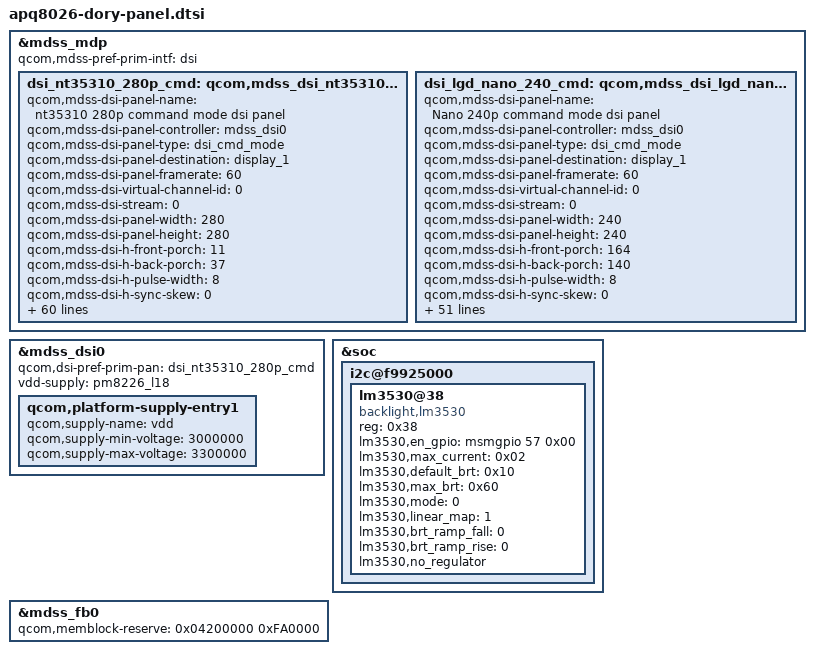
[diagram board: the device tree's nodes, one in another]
/* Copyright (c) 2013, Code Aurora Forum. All rights reserved.
 * Copyright (c) 2013, LGE Inc.
 *
 * This program is free software; you can redistribute it and/or modify
 * it under the terms of the GNU General Public License version 2 and
 * only version 2 as published by the Free Software Foundation.
 *
 * This program is distributed in the hope that it will be useful,
 * but WITHOUT ANY WARRANTY; without even the implied warranty of
 * MERCHANTABILITY or FITNESS FOR A PARTICULAR PURPOSE.  See the
 * GNU General Public License for more details.
 */

&mdss_mdp {
	qcom,mdss-pref-prim-intf = "dsi";
	dsi_nt35310_280p_cmd: qcom,mdss_dsi_nt35310_280p_cmd {
		qcom,mdss-dsi-panel-name = "nt35310 280p command mode dsi panel";
		qcom,mdss-dsi-panel-controller = <&mdss_dsi0>;
		qcom,mdss-dsi-panel-type = "dsi_cmd_mode";
		qcom,mdss-dsi-panel-destination = "display_1";
		qcom,mdss-dsi-panel-framerate = <60>;
		qcom,mdss-dsi-virtual-channel-id = <0>;
		qcom,mdss-dsi-stream = <0>;
		qcom,mdss-dsi-panel-width = <280>;
		qcom,mdss-dsi-panel-height = <280>;
		qcom,mdss-dsi-h-front-porch = <11>;
		qcom,mdss-dsi-h-back-porch = <37>;
		qcom,mdss-dsi-h-pulse-width = <8>;
		qcom,mdss-dsi-h-sync-skew = <0>;
		qcom,mdss-dsi-v-back-porch = <16>;
		qcom,mdss-dsi-v-front-porch = <30>;
		qcom,mdss-dsi-v-pulse-width = <1>;
		qcom,mdss-dsi-h-left-border = <0>;
		qcom,mdss-dsi-h-right-border = <0>;
		qcom,mdss-dsi-v-top-border = <0>;
		qcom,mdss-dsi-v-bottom-border = <0>;
		qcom,mdss-pan-physical-width-dimension = < 30 >;
		qcom,mdss-pan-physical-height-dimension = < 30 >;
		qcom,mdss-dsi-bpp = <24>;
		qcom,mdss-dsi-color-order = <0>;
		qcom,mdss-dsi-underflow-color = <0xff>;
		qcom,mdss-dsi-border-color = <0>;
		qcom,mdss-dsi-on-command = [
			39 01 00 00 00 00 03 ED 01 FE /* unlock cmd2 */
			39 01 00 00 00 00 06 3B 43 74 74 28 32 /* VBP, VFP, HBP, HFP setting */
			39 01 00 00 00 00 02 36 D4 /* SET_ADDRESS_MODE */
			39 01 00 00 00 00 02 3A 76 /* SET_PIXEL_FORMAT */
			39 01 00 00 00 00 02 26 01 /* SET_GAMMA_CURVE */
			39 01 00 00 00 00 02 35 00 /* SET_TEAR_ON */
			39 01 00 00 00 00 03 44 00 00 /* SET_TEAR_LINE */
			39 01 00 00 00 00 05 30 00 C8 01 DF /*SET_PARTIAL_LINE*/
			05 01 00 00 00 00 01 12 /*ENTER_PARTIAL_MODE*/
			39 01 00 00 00 00 02 B0 00 /* DISPLAY_CTRL */
			39 01 00 00 00 00 04 B1 1C 1C 04 /* front & backporch setting */
			39 01 00 00 00 00 04 B2 8D 8D 8D /* framerate */
			39 01 00 00 00 00 02 B4 3F /* Column Inv */
			39 01 00 00 00 00 02 B7 20 /* DISPLAY_CTRL2 REV ON */
			39 01 00 00 00 00 05 C0 50 50 00 00 /* PWR_CTRL1(GVDDP/N) : +4.8V/-4.8V */
			39 01 00 00 00 00 02 C4 78 /* PWR_CTRL5(Vcom 40(Default)) */
			39 01 00 00 00 00 05 C5 4C 11 11 11
			39 01 00 00 00 00 02 BF AA /* set the register to CMD2_P1 Register(E0h ~ E8h, 00h, EFh) */
			39 01 00 00 00 00 02 DF 10 /* SLEEP OUT OTP Read off */
			39 01 00 00 00 00 25 E0 /* GMACTRL1 */
			01 00 34 00 42 00
			4E 00 4F 00 5F 00
			65 00 77 00 86 00
			92 00 A0 00 B1 00
			C0 00 C6 00 DC 00
			D5 00 DC 00 FF 00
			39 01 00 00 00 00 25 E1 /* GMACTRL2 */
			01 00 34 00 42 00
			4E 00 4F 00 5F 00
			65 00 77 00 86 00
			92 00 A0 00 B1 00
			C0 00 C6 00 DC 00
			D5 00 DC 00 FF 00
			39 01 00 00 00 00 25 E2 /* GMACTRL3 */
			39 00 40 00 44 00
			4E 00 4F 00 5F 00
			65 00 77 00 86 00
			92 00 A0 00 B1 00
			C0 00 C6 00 DC 00
			D5 00 DC 00 FF 00
			39 01 00 00 00 00 25 E3 /* GMACTRL4 */
			39 00 40 00 44 00
			4E 00 4F 00 5F 00
			65 00 77 00 86 00
			92 00 A0 00 B1 00
			C0 00 C6 00 DC 00
			D5 00 DC 00 FF 00
			39 01 00 00 00 00 25 E4 /* GMACTRL5 */
			39 00 40 00 44 00
			4E 00 4F 00 5F 00
			65 00 77 00 86 00
			92 00 A0 00 B1 00
			C0 00 C6 00 DC 00
			D5 00 DC 00 FF 00
			39 01 00 00 00 00 25 E5 /* GMACTRL6 */
			39 00 40 00 44 00
			4E 00 4F 00 5F 00
			65 00 77 00 86 00
			92 00 A0 00 B1 00
			C0 00 C6 00 DC 00
			D5 00 DC 00 FF 00
			39 01 00 00 00 00 05 E9 AA 00 00 00
			39 01 00 00 00 00 02 00 AA
			05 01 00 00 0A 00 01 11
			39 01 00 00 00 00 05 2A 00 14 01 2B /* Set Hori address 21~300(280) */
			39 01 00 00 00 00 05 2B 00 C8 01 DF /* Set Vert address 200~479(280) */
			05 01 00 00 00 00 01 29];
		qcom,mdss-dsi-off-command = [
			05 01 00 00 05 00 01 28
			05 01 00 00 A0 00 01 10];
		qcom,mdss-dsi-on-command-state = "dsi_hs_mode";
		qcom,mdss-dsi-off-command-state = "dsi_hs_mode";
		qcom,mdss-dsi-idle-on-command = [05 01 00 00 01 00 01 39];
		qcom,mdss-dsi-idle-on-command-state = "dsi_hs_mode";
		qcom,mdss-dsi-idle-off-command = [05 01 00 00 01 00 01 38];
		qcom,mdss-dsi-idle-off-command-state = "dsi_hs_mode";
		qcom,mdss-dsi-low-fps-mode-on-command = [39 01 00 00 00 00 04 B2 8D A5 A5];
		qcom,mdss-dsi-low-fps-mode-on-command-state = "dsi_hs_mode";
		qcom,mdss-dsi-low-fps-mode-off-command = [39 01 00 00 00 00 04 B2 8D 8D 8D];
		qcom,mdss-dsi-low-fps-mode-off-command-state = "dsi_hs_mode";
		qcom,mdss-dsi-h-sync-pulse = <1>;
		qcom,mdss-dsi-traffic-mode = "burst_mode";
		qcom,mdss-dsi-lane-map = "lane_map_0123";
		qcom,mdss-dsi-bllp-eof-power-mode;
		qcom,mdss-dsi-bllp-power-mode;
		qcom,mdss-dsi-lane-0-state;
		qcom,mdss-dsi-te-pin-select = <1>;
		qcom,mdss-dsi-te-v-sync-rd-ptr-irq-line = <0x2c>;
		qcom,mdss-dsi-te-dcs-command = <1>;
		qcom,mdss-dsi-te-check-enable;
		qcom,mdss-dsi-te-using-te-pin;
		qcom,mdss-dsi-panel-timings = [3F 10 03 00 19 19 0E 12 0E 03 04 00];
		qcom,mdss-dsi-t-clk-post = <0x32>;
		qcom,mdss-dsi-t-clk-pre = <0x37>;
		qcom,mdss-dsi-bl-pmic-pwm-frequency = <100>;
		qcom,mdss-dsi-bl-min-level = <1>;
		qcom,mdss-dsi-bl-max-level = <255>;
		qcom,mdss-dsi-dma-trigger = "trigger_sw";
		qcom,mdss-dsi-mdp-trigger = "none";
		qcom,mdss-dsi-reset-sequence = <1 10>, <0 10>, <1 10>;
		qcom,mdss-dsi-bl-pmic-control-type = "bl_external";
		qcom,ulps-enabled;

		qcom,cont-splash-enabled;
	};

	dsi_lgd_nano_240_cmd: qcom,mdss_dsi_lgd_nano_240_cmd {
		qcom,mdss-dsi-panel-name = "Nano 240p command mode dsi panel";
		qcom,mdss-dsi-panel-controller = <&mdss_dsi0>;
		qcom,mdss-dsi-panel-type = "dsi_cmd_mode";
		qcom,mdss-dsi-panel-destination = "display_1";
		qcom,mdss-dsi-panel-framerate = <60>;
		qcom,mdss-dsi-virtual-channel-id = <0>;
		qcom,mdss-dsi-stream = <0>;
		qcom,mdss-dsi-panel-width = <240>;
		qcom,mdss-dsi-panel-height = <240>;
		qcom,mdss-dsi-h-front-porch = <164>;
		qcom,mdss-dsi-h-back-porch = <140>;
		qcom,mdss-dsi-h-pulse-width = <8>;
		qcom,mdss-dsi-h-sync-skew = <0>;
		qcom,mdss-dsi-v-back-porch = <1>;
		qcom,mdss-dsi-v-front-porch = <6>;
		qcom,mdss-dsi-v-pulse-width = <1>;
		qcom,mdss-dsi-h-left-border = <0>;
		qcom,mdss-dsi-h-right-border = <0>;
		qcom,mdss-dsi-v-top-border = <0>;
		qcom,mdss-dsi-v-bottom-border = <0>;
		qcom,mdss-pan-physical-width-dimension = < 28 >;
		qcom,mdss-pan-physical-height-dimension = < 28 >;
		qcom,mdss-dsi-bpp = <24>;
		qcom,mdss-dsi-color-order = <0>;
		qcom,mdss-dsi-underflow-color = <0xff>;
		qcom,mdss-dsi-border-color = <0>;
		qcom,mdss-dsi-on-command = [
			05 01 00 00 A0 00 01 11
			15 01 00 00 00 00 02 36 D8
			05 01 00 00 00 00 01 29];
		qcom,mdss-dsi-off-command = [
			05 01 00 00 05 00 01 28
			29 01 00 00 00 00 03 F1 5A 5A
			29 01 00 00 00 00 0F F4
			07 00 00 00 21 4F
			01 0E 2A 66 02 2A
			00 02
			29 01 00 00 00 00 03 F1 A5 A5
			05 01 00 00 A0 00 01 10];
		qcom,mdss-dsi-on-command-state = "dsi_lp_mode";
		qcom,mdss-dsi-off-command-state = "dsi_hs_mode";
		qcom,mdss-dsi-idle-on-command = [05 01 00 00 01 00 01 39];
		qcom,mdss-dsi-idle-on-command-state = "dsi_hs_mode";
		qcom,mdss-dsi-idle-off-command = [05 01 00 00 01 00 01 38];
		qcom,mdss-dsi-idle-off-command-state = "dsi_hs_mode";
		qcom,mdss-dsi-h-sync-pulse = <1>;
		qcom,mdss-dsi-traffic-mode = "burst_mode";
		qcom,mdss-dsi-lane-map = "lane_map_0123";
		qcom,mdss-dsi-bllp-eof-power-mode;
		qcom,mdss-dsi-bllp-power-mode;
		qcom,mdss-dsi-lane-0-state;
		qcom,mdss-dsi-te-pin-select = <1>;
		qcom,mdss-dsi-te-v-sync-rd-ptr-irq-line = <0x2c>;
		qcom,mdss-dsi-te-dcs-command = <1>;
		qcom,mdss-dsi-te-check-enable;
		qcom,mdss-dsi-te-using-te-pin;
		qcom,mdss-dsi-panel-timings = [3A 11 0C 00 1E 1D 10 13 12 03 04 00];
		qcom,mdss-dsi-t-clk-post = <0x1f>;
		qcom,mdss-dsi-t-clk-pre = <0x2c>;
		qcom,mdss-dsi-bl-min-level = <1>;
		qcom,mdss-dsi-bl-max-level = <255>;
		qcom,mdss-dsi-dma-trigger = "trigger_sw";
		qcom,mdss-dsi-mdp-trigger = "none";
		qcom,mdss-dsi-reset-sequence = <1 10>, <0 10>, <1 160>;
		qcom,mdss-dsi-bl-pmic-control-type = "bl_external";

		qcom,cont-splash-enabled;
	};
};

&mdss_dsi0 {
	qcom,dsi-pref-prim-pan = <&dsi_nt35310_280p_cmd>;
	vdd-supply = <&pm8226_l18>;
	qcom,platform-supply-entry1 {
		qcom,supply-name = "vdd";
		qcom,supply-min-voltage = <3000000>;
		qcom,supply-max-voltage = <3300000>;
	};
};

&soc {
	i2c@f9925000 { /* BLSP1 QUP2 */
		lm3530@38 {
			compatible = "backlight,lm3530";
			status = "ok";
			reg = <0x38>;
			lm3530,en_gpio = <&msmgpio 57 0x00>;
			lm3530,max_current = /bits/ 8 <0x02>;
			lm3530,default_brt = /bits/ 8 <0x10>;
			lm3530,max_brt = /bits/ 8 <0x60>;
			lm3530,mode = /bits/ 8 <0>; /* Manual Mode */
			lm3530,linear_map = /bits/ 8 <1>; /* Linear map */
			lm3530,brt_ramp_fall = /bits/ 8 <0>;
			lm3530,brt_ramp_rise = /bits/ 8 <0>;
			lm3530,no_regulator;
		};
	};
};

&mdss_fb0 {
	qcom,memblock-reserve = <0x04200000 0xFA0000>;
};
